# platform_designer_hps_system_hps_0_hps register map
Vendor: default_vendor.com; File version: 0.0
Registers are 32-bit, read-write, reset 0x0 unless marked. A register's access mark holds for its fields unless they carry their own. Offsets are from the block's base; [hi:lo] are bit positions; {n}, {i} and the like mark numbered series; 'fields as' and 'values as' point back to an identical list.

## usb0 (part 4 of 4) — Registers in the USB OTG Controller Module. Only the Core Global, Power and Clock Gating, Data FIFO Access, and Host Port registers can be accessedin both Host and Device modes. When the USB OTG Controller is operating in one mode, either Device or Host, the application must not access registers from the other mode. If an illegal access occurs, a Mode Mismatch interrupt is generated and reflected in the Core Interrupt register (GINTSTS.ModeMis). When the core switches from one mode to another, the registers in the new mode must be reprogrammed as they would be after a power-on reset. The register address map is fixed and does not depend on the module configuration (for example, how many endpoints are implemented). Host and Device mode registers occupy different addresses.
Base 0xFFB00000
Same registers: usb1 0xFFB40000
0x918 devgrp_dtxfsts0 ro reset 0x2000 — This register contains the free space information for the Device IN endpoint TxFIFO.
  [15:0] ineptxfspcavail — Indicates the amount of free space available in the Endpoint TxFIFO. Values are in terms of 32-bit words. 16'h0: Endpoint TxFIFO is full 16'h1: 1 word available 16'h2: 2 words available 16'hn: n words available (where 0 n 32,768) 16'h8000: 32,768 words available Others: Reserved
0x91C devgrp_diepdmab0 ro reset not defined — Endpoint 16.
  [31:0] diepdmab0 — Used with Scatter/Gather DMA.
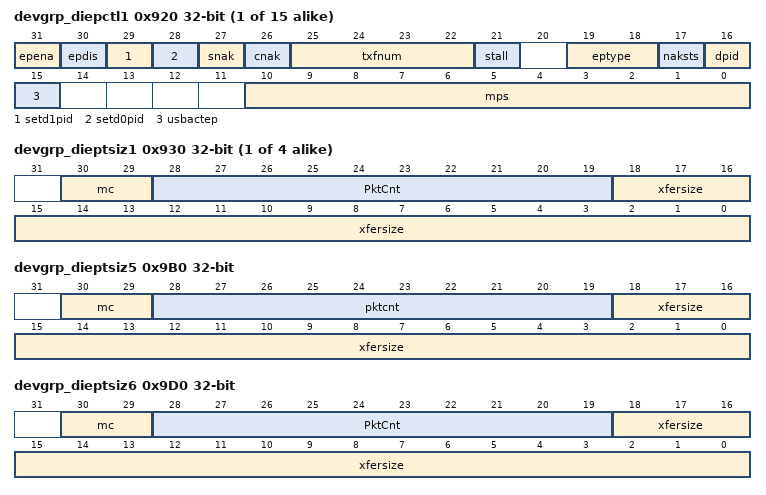
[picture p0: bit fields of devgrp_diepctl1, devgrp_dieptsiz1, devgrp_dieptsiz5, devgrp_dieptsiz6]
{0x900+0x20*i} devgrp_diepctl{i} (i=1..15) — Endpoint_number: {i}
  [31] epena ro — Applies to IN and OUT endpoints. -When Scatter/Gather DMA mode is enabled, -for IN endpoints this bit indicates that the descriptor structure and data buffer with data ready to transmit is setup. -for OUT endpoint it indicates that the descriptor structure and data buffer to receive data is setup. -When Scatter/Gather DMA mode is enabled such as for buffer-pointer based DMA mode: - for IN endpoints, this bit indicates that data is ready to be transmitted on the endpoint. - for OUT endpoints, this bit indicates that the application has allocated the memory to start receiving data from the USB. - The core clears this bit before setting any of the following interrupts on this endpoint: -SETUP Phase Done -Endpoint Disabled -Transfer Completed for control endpoints in DMA mode, this bit must be set to be able to transfer SETUP data packets in memory.
    0=inactive; 1=active
  [30] epdis ro — Applies to IN and OUT endpoints. The application sets this bit to stop transmitting/receiving data on an endpoint, even before the transfer for that endpoint is complete. The application must wait for the Endpoint Disabled interrupt before treating the endpoint as disabled. The core clears this bit before setting the Endpoint Disabled interrupt. The application must set this bit only if Endpoint Enable is already set for this endpoint.
    0=inactive; 1=active
  [29] setd1pid wo — Applies to interrupt/bulk IN and OUT endpoints only. Writing to this field sets the Endpoint Data PID (DPID) field in this register to DATA1. This field is applicable both for Scatter/Gather DMA mode and non-Scatter/Gather DMA mode. Set Odd (micro)frame (SetOddFr) Applies to isochronous IN and OUT endpoints only. Writing to this field sets the Even/Odd (micro)frame (EO_FrNum) field to odd (micro)frame.This field is not applicable for Scatter/Gather DMA mode.
    0=disabled; 1=enabled
  [28] setd0pid wo — Applies to interrupt/bulk IN and OUT endpoints only. Writing to this field sets the Endpoint Data PID (DPID) field in this register to DATA0. This field is applicable both for Scatter/Gather DMA mode and non-Scatter/Gather DMA mode. In non-Scatter/Gather DMA mode: Set Even (micro)frame (SetEvenFr) Applies to isochronous IN and OUT endpoints only. Writing to this field sets the Even/Odd (micro)frame (EO_FrNum) field to even (micro) frame. When Scatter/Gather DMA mode is enabled, this field is reserved. The frame number in which to send data is in the transmit descriptor structure. The frame in which to receive data is updated in receive descriptor structure.
    0=disabled; 1=enabled
  [27] snak wo — A write to this bit sets the NAK bit for the endpoint. Using this bit, the application can control the transmission of NAK handshakes on an endpoint. The core can also Set this bit for an endpoint after a SETUP packet is received on that endpoint.
    0=inactive; 1=active
  [26] cnak wo — A write to this bit clears the NAK bit for the endpoint.
    0=inactive; 1=active
  [25:22] txfnum — Shared FIFO Operation-non-periodic endpoints must set this bit to zero. Periodic endpoints must map this to the corresponding Periodic TxFIFO number. 4'h0: Non-Periodic TxFIFO Others: Specified Periodic TxFIFO.number An interrupt IN endpoint can be configured as a non-periodic endpoint for applications such as mass storage. The core treats an IN endpoint as a non-periodic endpoint if the TxFNum field is set to 0. Configuring an interrupt IN endpoint as a non-periodic endpoint saves the extra periodic FIFO area. Dedicated FIFO Operation-these bits specify the FIFO number associated with this endpoint. Each active IN endpoint must be programmed to a separate FIFO number. This field is valid only for IN endpoints.
  [21] stall ro — Applies to non-control, non-isochronous IN and OUT endpoints only. The application sets this bit to stall all tokens from the USB host to this endpoint. If a NAK bit, Global Non-periodic IN NAK, or Global OUT NAK is set along with this bit, the STALL bit takes priority. Only the application can clear this bit, never the core. Applies to control endpoints only. The application can only set this bit, and the core clears it, when a SETUP token is received for this endpoint. If a NAK bit, Global Non-periodic IN NAK, or Global OUT NAK is set along with this bit, the STALL bit takes priority. Irrespective of this bit's setting, the core always responds to SETUP data packets with an ACK handshake.
    0=inactive; 1=active
  [19:18] eptype — This is the transfer type supported by this logical endpoint.
    0=control; 1=isochronous; 2=bulk; 3=interrup
  [17] naksts ro — When either the application or the core sets this bit: -The core stops receiving any data on an OUT endpoint, even if there is space in the RxFIFO to accommodate the incoming packet. -for non-isochronous IN endpoints: The core stops transmitting any data on an IN endpoint, even if there data is available in the TxFIFO. -for isochronous IN endpoints: The core sends out a zero-length data packet, even if there data is available in the TxFIFO. Irrespective of this bit's setting, the core always responds to SETUP data packets with an ACK handshake.
    0=nonnak; 1=nak
  [16] dpid ro — Applies to interrupt/bulk IN and OUT endpoints only. Contains the PID of the packet to be received or transmitted on this endpoint. The application must program the PID of the first packet to be received or transmitted on this endpoint, after the endpoint is activated. The applications use the SetD1PID and SetD0PID fields of this register to program either DATA0 or DATA1 PID. 0: DATA0 1: DATA1This field is applicable both for Scatter/Gather DMA mode and non-Scatter/Gather DMA mode. Even/Odd (Micro)Frame (EO_FrNum) In non-Scatter/Gather DMA mode: Applies to isochronous IN and OUT endpoints only. Indicates the (micro)frame number in which the core transmits/receives isochronous data for this endpoint. The application must program the even/odd (micro) frame number in which it intends to transmit/receive isochronous data for this endpoint using the SetEvnFr and SetOddFr fields in this register. 0: Even (micro)frame 1: Odd (micro)frame When Scatter/Gather DMA mode is enabled, this field is reserved. The frame number in which to send data is provided in the transmit descriptor structure. The frame in which data is received is updated in receive descriptor structure.
    0=inactive; 1=active
  [15] usbactep — Indicates whether this endpoint is active in the current configuration and interface. The core clears this bit for all endpoints (other than EP 0) after detecting a USB reset. After receiving the SetConfiguration and SetInterface commands, the application must program endpoint registers accordingly and set this bit.
    0=disabled; 1=enabled
  [10:0] mps — Applies to IN and OUT endpoints. The application must program this field with the maximum packet size for the current logical endpoint. This value is in bytes.
{0x910+0x20*i} devgrp_dieptsiz{i} (i=1..4) — The application must modify this register before enabling the endpoint. Once the endpoint is enabled using Endpoint Enable bit of the Device Endpoint-n Control registers (DIEPCTLn.EPEna/DOEPCTLn.EPEna), the core modifies this register. The application can only read this register once the core has cleared the Endpoint Enable bit.
  [30:29] mc — for periodic IN endpoints, this field indicates the number of packets that must be transmitted per microframe on the USB. The core uses this field to calculate the data PID for isochronous IN endpoints. for non-periodic IN endpoints, this field is valid only in Internal DMA mode. It specifies the number of packets the core must fetchfor an IN endpoint before it switches to the endpoint pointed to by the Next Endpoint field of the Device Endpoint-n Control register (DIEPCTLn.NextEp)
    1=packetone; 2=packettwo; 3=packetthree
  [28:19] PktCnt — Indicates the total number of USB packets that constitute the Transfer Size amount of data for endpoint 0.This field is decremented every time a packet (maximum size or short packet) is read from the TxFIFO.
  [18:0] xfersize — Indicates the transfer size in bytes for endpoint 0. The core interrupts the application only after it has exhausted the transfer size amount of data. The transfer size can be Set to the maximum packet size of the endpoint, to be interrupted at the end of each packet. The core decrements this field every time a packet from the external memory is written to the TxFIFO.
0x938 devgrp_dtxfsts1 ro reset 0x2000 — This register contains the free space information for the Device IN endpoint TxFIFO.
  fields as devgrp_dtxfsts0
{0x91C+0x20*i} devgrp_diepdmab{i} ro reset not defined (i=1..4) — DMA Buffer Address.
  [31:0] diepdmab{i} — Holds the current buffer address. This register is updated as and when the data transfer for the corresponding end point is in progress. This register is present only in Scatter/Gather DMA mode.
0x958 devgrp_DTXFSTS2 ro reset 0x2000 — This register contains the free space information for the Device IN endpoint TxFIFO.
  fields as devgrp_dtxfsts0
{0x918+0x20*i} devgrp_dtxfsts{i} ro reset 0x2000 (i=3..15) — This register contains the free space information for the Device IN endpoint TxFIFO.
  fields as devgrp_dtxfsts0
0x9B0 devgrp_dieptsiz5 — The application must modify this register before enabling the endpoint. Once the endpoint is enabled using Endpoint Enable bit of the Device Endpoint-n Control registers (DIEPCTLn.EPEna/DOEPCTLn.EPEna), the core modifies this register. The application can only read this register once the core has cleared the Endpoint Enable bit.
  [30:29] mc — for periodic IN endpoints, this field indicates the number of packets that must be transmitted per microframe on the USB. The core uses this field to calculate the data PID for isochronous IN endpoints. for non-periodic IN endpoints, this field is valid only in Internal DMA mode. It specifies the number of packets the core must fetchfor an IN endpoint before it switches to the endpoint pointed to by the Next Endpoint field of the Device Endpoint-n Control register (DIEPCTLn.NextEp)
    1=packetone; 2=packettwo; 3=packetthree
  [28:19] pktcnt — Indicates the total number of USB packets that constitute the Transfer Size amount of data for endpoint 0.This field is decremented every time a packet (maximum size or short packet) is read from the TxFIFO.
  [18:0] xfersize — Indicates the transfer size in bytes for endpoint 0. The core interrupts the application only after it has exhausted the transfer size amount of data. The transfer size can be Set to the maximum packet size of the endpoint, to be interrupted at the end of each packet. The core decrements this field every time a packet from the external memory is written to the TxFIFO.
0x9BC devgrp_diepdmab5 ro reset not defined — Device IN Endpoint 1 Buffer Address.
  [31:0] diepdmab5 — Holds the current buffer address. This register is updated as and when the data transfer for the corresponding end point is in progress. This register is present only in Scatter/Gather DMA mode.
0x9D0 devgrp_dieptsiz6 — The application must modify this register before enabling the endpoint. Once the endpoint is enabled using Endpoint Enable bit of the Device Endpoint-n Control registers (DIEPCTLn.EPEna/DOEPCTLn.EPEna), the core modifies this register. The application can only read this register once the core has cleared the Endpoint Enable bit.
  fields as devgrp_dieptsiz1
{0x91C+0x20*i} devgrp_diepdmab{i} ro reset not defined (i=6..15) — DMA Buffer Address.
  fields as devgrp_diepdmab1
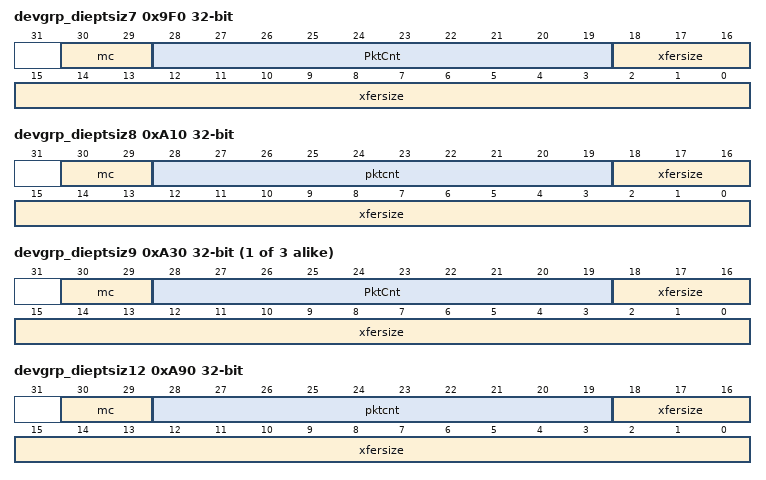
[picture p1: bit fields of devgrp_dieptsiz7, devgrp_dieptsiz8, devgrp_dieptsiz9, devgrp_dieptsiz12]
0x9F0 devgrp_dieptsiz7 — The application must modify this register before enabling the endpoint. Once the endpoint is enabled using Endpoint Enable bit of the Device Endpoint-n Control registers (DIEPCTLn.EPEna/DOEPCTLn.EPEna), the core modifies this register. The application can only read this register once the core has cleared the Endpoint Enable bit.
  fields as devgrp_dieptsiz1
0xA10 devgrp_dieptsiz8 — The application must modify this register before enabling the endpoint. Once the endpoint is enabled using Endpoint Enable bit of the Device Endpoint-n Control registers (DIEPCTLn.EPEna/DOEPCTLn.EPEna), the core modifies this register. The application can only read this register once the core has cleared the Endpoint Enable bit.
  fields as devgrp_dieptsiz5
{0x910+0x20*i} devgrp_dieptsiz{i} (i=9..11) — The application must modify this register before enabling the endpoint. Once the endpoint is enabled using Endpoint Enable bit of the Device Endpoint-n Control registers (DIEPCTLn.EPEna/DOEPCTLn.EPEna), the core modifies this register. The application can only read this register once the core has cleared the Endpoint Enable bit.
  fields as devgrp_dieptsiz1
0xA90 devgrp_dieptsiz12 — The application must modify this register before enabling the endpoint. Once the endpoint is enabled using Endpoint Enable bit of the Device Endpoint-n Control registers (DIEPCTLn.EPEna/DOEPCTLn.EPEna), the core modifies this register. The application can only read this register once the core has cleared the Endpoint Enable bit.
  fields as devgrp_dieptsiz5
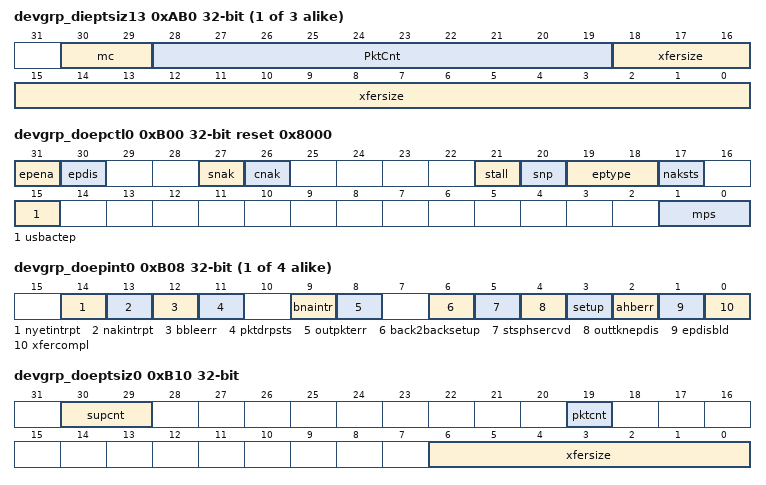
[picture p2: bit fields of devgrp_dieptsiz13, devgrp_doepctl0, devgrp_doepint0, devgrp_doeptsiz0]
{0x910+0x20*i} devgrp_dieptsiz{i} (i=13..15) — The application must modify this register before enabling the endpoint. Once the endpoint is enabled using Endpoint Enable bit of the Device Endpoint-n Control registers (DIEPCTLn.EPEna/DOEPCTLn.EPEna), the core modifies this register. The application can only read this register once the core has cleared the Endpoint Enable bit.
  fields as devgrp_dieptsiz1
0xB00 devgrp_doepctl0 reset 0x8000 — This is Control OUT Endpoint 0 Control register.
  [31] epena ro — When Scatter/Gather DMA mode is enabled, for OUT endpoints this bit indicates that the descriptor structure and data buffer to receive data is setup. When Scatter/Gather DMA mode is disabled(such as for buffer-pointer based DMA mode)this bit indicates that the application has allocated the memory to start receiving data from the USB.The core clears this bit before setting any of the following interrupts on this endpoint: SETUP Phase Done Endpoint Disabled Transfer Completed In DMA mode, this bit must be Set for the core to transfer SETUP data packets into memory.
    0=inactive; 1=active
  [30] epdis ro — The application cannot disable control OUT endpoint 0.
    0=inactive
  [27] snak wo — A write to this bit sets the NAK bit for the endpoint.Using this bit, the application can control the transmission of NAK handshakes on an endpoint. The core can also Set bit on a Transfer Completed interrupt, or after a SETUP is received on the endpoint.
    0=noset; 1=set
  [26] cnak wo — A write to this bit clears the NAK bit for the endpoint.
    0=noclear; 1=clear
  [21] stall ro — The application can only Set this bit, and the core clears it, when a SETUP token is received for this endpoint. If a NAK bit or Global OUT NAK is Set along with this bit, the STALL bit takes priority. Irrespective of this bit's setting, the core always responds to SETUP data packets with an ACK handshake.
    0=inactive; 1=active
  [20] snp — This bit configures the endpoint to Snoop mode. In Snoop mode, the core does not check the correctness of OUT packets before transferring them to application memory.
    0=disabled; 1=enabled
  [19:18] eptype ro — Hardcoded to 0 for control.
    0=active
  [17] naksts ro — When either the application or the core sets this bit, the core stops receiving data, even If there is space in the RxFIFO to accommodate the incoming packet. Irrespective of this bit's setting, the core always responds to SETUP data packets with an ACK handshake.
    0=inactive; 1=active
  [15] usbactep ro — This bit is always Set to 1, indicating that a control endpoint 0 is always active in all configurations and interfaces.
    1=active
  [1:0] mps ro — The maximum packet size for control OUT endpoint 0 is thesame as what is programmed in control IN Endpoint 0.
    0=byte64; 1=byte32; 2=byte16; 3=byte8
{0xB08+0x20*i} devgrp_doepint{i} ro (i=0..3) — This register indicates the status of an endpoint with respect to USB- and AHB-related events. The application must read this register when the OUT Endpoints Interrupt bit or IN Endpoints Interrupt bit of the Core Interrupt register (GINTSTS.OEPInt or GINTSTS.IEPInt, respectively) is set. Before the application can read this register, it must first read the Device All Endpoints Interrupt (DAINT) register to get the exact endpoint number for the Device Endpoint-n Interrupt register. The application must clear the appropriate bit in this register to clear the corresponding bits in the DAINT and GINTSTS registers.
  [all] fields
    0=inactive; 1=active
  [14] nyetintrpt — The core generates this interrupt when a NYET response is transmitted for a non isochronous OUT endpoint.
  [13] nakintrpt — The core generates this interrupt when a NAK is transmitted or received by the device. In case of isochronous IN endpoints the interrupt gets generated when a zero length packet is transmitted due to un-availability of data in the TXFifo.
  [12] bbleerr — The core generates this interrupt when babble is received for the endpoint.
  [11] pktdrpsts — This bit indicates to the application that an ISOC OUT packet has been dropped. This bit does not have an associated mask bit and does not generate an interrupt.
  [9] bnaintr — This bit is valid only when Scatter/Gather DMA mode is This bit is valid only when Scatter/Gather DMA mode is enabled. The core generates this interrupt when the descriptor accessed is not ready for the Core to process, such as Host busy or DMA done
  [8] outpkterr — Applies to OUT endpoints Only This interrupt is asserted when the core detects an overflow or a CRC error for non-Isochronous OUT packet.
  [6] back2backsetup — Applies to Control OUT endpoints only. This bit indicates that the core has received more than three back-to-back SETUP packets for this particular endpoint. for information about handling this interrupt,
  [5] stsphsercvd — This interrupt is valid only for Control OUT endpoints and only in Scatter Gather DMA mode. This interrupt is generated only after the core has transferred all the data that the host has sent during the data phase of a control write transfer, to the system memory buffer. The interrupt indicates to the application that the host has switched from data phase to the status phase of a Control Write transfer. The application can use this interrupt to ACK or STALL the Status phase, after it has decoded the data phase. This is applicable only in Case of Scatter Gather DMA mode.
  [4] outtknepdis — Applies only to control OUT endpoints. Indicates that an OUT token was received when the endpoint was not yet enabled. This interrupt is asserted on the endpoint for which the OUT token was received.
  [3] setup — Applies to control OUT endpoints only. Indicates that the SETUP phase for the control endpoint is complete and no more back-to-back SETUP packets were received for the current control transfer. On this interrupt, the application can decode the received SETUP data packet.
  [2] ahberr — Applies to IN and OUT endpoints.This is generated only in Internal DMA mode when there is an AHB error during an AHB read/write. The application can read the corresponding endpoint DMA address register to get the error address.
  [1] epdisbld — Applies to IN and OUT endpoints. This bit indicates that the endpoint is disabled per the application's request.
  [0] xfercompl — Applies to IN and OUT endpoints.When Scatter/Gather DMA mode is enabled This field indicates that the requested data from the internal FIFO is moved to external system memory. This interrupt is generated only when the corresponding endpoint descriptor is closed, and the IOC bit for the corresponding descriptor is Set. When Scatter/Gather DMA mode is disabled, this field indicates that the programmed transfer is complete on the AHB as well as on the USB, for this endpoint.
0xB10 devgrp_doeptsiz0 — The application must modify this register before enabling endpoint 0. Once endpoint 0 is enabled using Endpoint Enable bit of the Device Control Endpoint 0 Control registers (DIEPCTL0.EPEna/DOEPCTL0.EPEna), the core modifies this register. The application can only read this register once the core has cleared the Endpoint Enable bit. Nonzero endpoints use the registers for endpoints 1 to 15. When Scatter/Gather DMA mode is enabled, this register must not be programmed by the application. If the application reads this register when Scatter/Gather DMA mode is enabled, the core returns all zeros.
  [30:29] supcnt — SETUP Packet Count (SUPCnt)This field specifies the number of back-to-back SETUP datapackets the endpoint can receive.
    1=onepacket; 2=twopacket; 3=threepacket
  [19] pktcnt — This field is decremented to zero after a packet is written into the RxFIFO.
  [6:0] xfersize — Indicates the transfer size in bytes for endpoint 0. The core interrupts the application only after it has exhausted the transfer size amount of data. The transfer size can be Set to the maximum packet size of the endpoint, to be interrupted at the end of each packet. The core decrements this field every time a packet from the external memory is written to the RxFIFO.
{0xB14+0x20*i} devgrp_doepdma{i} reset not defined (i=0..2) — DMA Addressing.
  [31:0] doepdma{i} — Holds the start address of the external memory for storing or fetching endpoint data. for control endpoints, this field stores control OUT data packets as well as SETUP transaction data packets. When more than three SETUP packets are received back-to-back, the SETUP data packet in the memory is overwritten. This register is incremented on every AHB transaction. The application can give only a DWORD-aligned address. When Scatter/Gather DMA mode is not enabled, the application programs the start address value in this field. When Scatter/Gather DMA mode is enabled, this field indicates the base pointer for the descriptor list.
0xB1C devgrp_doepdmab0 ro reset not defined — DMA Buffer Address.
  [31:0] doepdmab0 — Used with Scatter/Gather DMA.
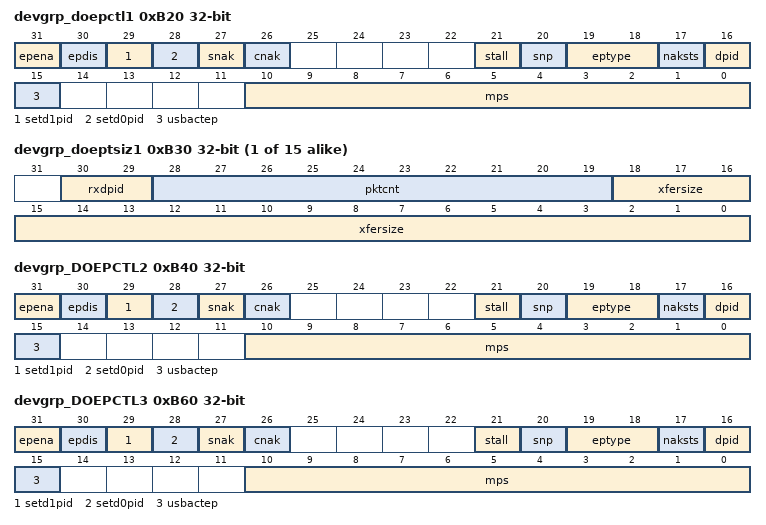
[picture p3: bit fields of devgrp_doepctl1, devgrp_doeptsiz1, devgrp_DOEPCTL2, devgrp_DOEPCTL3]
0xB20 devgrp_doepctl1 — Out Endpoint 1.
  [31] epena ro — Applies to IN and OUT endpoints. -When Scatter/Gather DMA mode is enabled, -for IN endpoints this bit indicates that the descriptor structure and data buffer with data ready to transmit is setup. -for OUT endpoint it indicates that the descriptor structure and data buffer to receive data is setup. -When Scatter/Gather DMA mode is enabled such as for buffer-pointer based DMA mode: - for IN endpoints, this bit indicates that data is ready to be transmitted on the endpoint. - for OUT endpoints, this bit indicates that the application has allocated the memory to start receiving data from the USB. - The core clears this bit before setting any of the following interrupts on this endpoint: -SETUP Phase Done -Endpoint Disabled -Transfer Completed for control endpoints in DMA mode, this bit must be set to be able to transfer SETUP data packets in memory.
    0=inactive; 1=active
  [30] epdis ro — Applies to IN and OUT endpoints. The application sets this bit to stop transmitting/receiving data on an endpoint, even before the transfer for that endpoint is complete. The application must wait for the Endpoint Disabled interrupt before treating the endpoint as disabled. The core clears this bit before setting the Endpoint Disabled interrupt. The application must set this bit only if Endpoint Enable is already set for this endpoint.
    0=inactive; 1=active
  [29] setd1pid wo — Applies to interrupt/bulk IN and OUT endpoints only. Writing to this field sets the Endpoint Data PID (DPID) field in this register to DATA1. This field is applicable both for Scatter/Gather DMA mode and non-Scatter/Gather DMA mode. Set Odd (micro)frame (SetOddFr) Applies to isochronous IN and OUT endpoints only. Writing to this field sets the Even/Odd (micro)frame (EO_FrNum) field to odd (micro)frame.This field is not applicable for Scatter/Gather DMA mode.
    0=disabled; 1=enabled
  [28] setd0pid wo — Applies to interrupt/bulk IN and OUT endpoints only. Writing to this field sets the Endpoint Data PID (DPID) field in this register to DATA0. This field is applicable both for Scatter/Gather DMA mode and non-Scatter/Gather DMA mode. In non-Scatter/Gather DMA mode: Set Even (micro)frame (SetEvenFr) Applies to isochronous IN and OUT endpoints only. Writing to this field sets the Even/Odd (micro)frame (EO_FrNum) field to even (micro) frame. When Scatter/Gather DMA mode is enabled, this field is reserved. The frame number in which to send data is in the transmit descriptor structure. The frame in which to receive data is updated in receive descriptor structure.
    0=disabled; 1=enabled
  [27] snak wo — A write to this bit sets the NAK bit for the endpoint. Using this bit, the application can control the transmission of NAK handshakes on an endpoint. The core can also Set this bit for an endpoint after a SETUP packet is received on that endpoint.
    0=inactive; 1=active
  [26] cnak wo — A write to this bit clears the NAK bit for the endpoint.
    0=inactive; 1=active
  [21] stall ro — Applies to non-control, non-isochronous IN and OUT endpoints only. The application sets this bit to stall all tokens from the USB host to this endpoint. If a NAK bit, Global Non-periodic IN NAK, or Global OUT NAK is set along with this bit, the STALL bit takes priority. Only the application can clear this bit, never the core. Applies to control endpoints only. The application can only set this bit, and the core clears it, when a SETUP token is received for this endpoint. If a NAK bit, Global Non-periodic IN NAK, or Global OUT NAK is set along with this bit, the STALL bit takes priority. Irrespective of this bit's setting, the core always responds to SETUP data packets with an ACK handshake.
    0=inactive; 1=active
  [20] snp — Applies to OUT endpoints only. This bit configures the endpoint to Snoop mode. In Snoop mode, the core does not check the correctness of OUT packets before transferring them to application memory.
    0=disable; 1=enable
  [19:18] eptype — This is the transfer type supported by this logical endpoint.
    0=control; 1=isochronous; 2=bulk; 3=interrup
  [17] naksts ro — When either the application or the core sets this bit: -The core stops receiving any data on an OUT endpoint, even if there is space in the RxFIFO to accommodate the incoming packet. -for non-isochronous IN endpoints: The core stops transmitting any data on an IN endpoint, even if there data is available in the TxFIFO. -for isochronous IN endpoints: The core sends out a zero-length data packet, even if there data is available in the TxFIFO. Irrespective of this bit's setting, the core always responds to SETUP data packets with an ACK handshake.
    0=nonnak; 1=nak
  [16] dpid ro — Applies to interrupt/bulk IN and OUT endpoints only. Contains the PID of the packet to be received or transmitted on this endpoint. The application must program the PID of the first packet to be received or transmitted on this endpoint, after the endpoint is activated. The applications use the SetD1PID and SetD0PID fields of this register to program either DATA0 or DATA1 PID. 0: DATA0 1: DATA1This field is applicable both for Scatter/Gather DMA mode and non-Scatter/Gather DMA mode. Even/Odd (Micro)Frame (EO_FrNum) In non-Scatter/Gather DMA mode: Applies to isochronous IN and OUT endpoints only. Indicates the (micro)frame number in which the core transmits/receives isochronous data for this endpoint. The application must program the even/odd (micro) frame number in which it intends to transmit/receive isochronous data for this endpoint using the SetEvnFr and SetOddFr fields in this register. h 1'b0'b0: Even (micro)frame 1: Odd (micro)frame When Scatter/Gather DMA mode is enabled, this field is reserved. The frame number in which to send data is provided in the transmit descriptor structure. The frame in which data is received is updated in receive descriptor structure.
    0=inactive; 1=active
  [15] usbactep — Indicates whether this endpoint is active in the current configuration and interface. The core clears this bit for all endpoints (other than EP 0) after detecting a USB reset. After receiving the SetConfiguration and SetInterface commands, the application must program endpoint registers accordingly and set this bit.
    0=disabled; 1=enabled
  [10:0] mps — Applies to IN and OUT endpoints. The application must program this field with the maximum packet size for the current logical endpoint. This value is in bytes.
{0xB10+0x20*i} devgrp_doeptsiz{i} (i=1..15) — The application must modify this register before enabling the endpoint. Once the endpoint is enabled using Endpoint Enable bit of the Device Endpoint-n Control registers (DIEPCTLn.EPEna/DOEPCTLn.EPEna), the core modifies this register. The application can only read this register once the core has cleared the Endpoint Enable bit.
  [30:29] rxdpid ro — Applies to isochronous OUT endpoints only.This is the data PID received in the last packet for this endpoint. Use datax. Applies to control OUT Endpoints only. Use packetx. This field specifies the number of back-to-back SETUP data packets the endpoint can receive.
    0=data0; 1=data2packet1; 2=data1packet2; 3=mdatapacket3
  [28:19] pktcnt — Indicates the total number of USB packets that constitute the Transfer Size amount of data for endpoint 0.This field is decremented every time a packet (maximum size or short packet) is read from the RxFIFO.
  [18:0] xfersize — Indicates the transfer size in bytes for endpoint 0. The core interrupts the application only after it has exhausted the transfer size amount of data. The transfer size can be Set to the maximum packet size of the endpoint, to be interrupted at the end of each packet. The core decrements this field every time a packet from the external memory is written to the RxFIFO.
{0xB1C+0x20*i} devgrp_doepdmab{i} ro reset not defined (i=1..15) — DMA Buffer Address.
  [31:0] doepdmab{i} — Holds the current buffer address. This register is updated as and when the data transfer for the corresponding end point is in progress. This register is present only in Scatter/Gather DMA mode.
0xB40 devgrp_DOEPCTL2 — Out Endpoint 2.
  [31] epena ro — Applies to IN and OUT endpoints. -When Scatter/Gather DMA mode is enabled, -for IN endpoints this bit indicates that the descriptor structure and data buffer with data ready to transmit is setup. -for OUT endpoint it indicates that the descriptor structure and data buffer to receive data is setup. -When Scatter/Gather DMA mode is enabled such as for buffer-pointer based DMA mode: - for IN endpoints, this bit indicates that data is ready to be transmitted on the endpoint. - for OUT endpoints, this bit indicates that the application has allocated the memory to start receiving data from the USB. - The core clears this bit before setting any of the following interrupts on this endpoint: -SETUP Phase Done -Endpoint Disabled -Transfer Completed for control endpoints in DMA mode, this bit must be set to be able to transfer SETUP data packets in memory.
    0=inactive; 1=active
  [30] epdis ro — Applies to IN and OUT endpoints. The application sets this bit to stop transmitting/receiving data on an endpoint, even before the transfer for that endpoint is complete. The application must wait for the Endpoint Disabled interrupt before treating the endpoint as disabled. The core clears this bit before setting the Endpoint Disabled interrupt. The application must set this bit only if Endpoint Enable is already set for this endpoint.
    0=inactive; 1=active
  [29] setd1pid wo — Applies to interrupt/bulk IN and OUT endpoints only. Writing to this field sets the Endpoint Data PID (DPID) field in this register to DATA1. This field is applicable both for Scatter/Gather DMA mode and non-Scatter/Gather DMA mode. Set Odd (micro)frame (SetOddFr) Applies to isochronous IN and OUT endpoints only. Writing to this field sets the Even/Odd (micro)frame (EO_FrNum) field to odd (micro)frame.This field is not applicable for Scatter/Gather DMA mode.
    0=disabled; 1=enabled
  [28] setd0pid wo — Applies to interrupt/bulk IN and OUT endpoints only. Writing to this field sets the Endpoint Data PID (DPID) field in this register to DATA0. This field is applicable both for Scatter/Gather DMA mode and non-Scatter/Gather DMA mode. In non-Scatter/Gather DMA mode: Set Even (micro)frame (SetEvenFr) Applies to isochronous IN and OUT endpoints only. Writing to this field sets the Even/Odd (micro)frame (EO_FrNum) field to even (micro) frame. When Scatter/Gather DMA mode is enabled, this field is reserved. The frame number in which to send data is in the transmit descriptor structure. The frame in which to receive data is updated in receive descriptor structure.
    0=disabled; 1=enabled
  [27] snak wo — A write to this bit sets the NAK bit for the endpoint. Using this bit, the application can control the transmission of NAK handshakes on an endpoint. The core can also Set this bit for an endpoint after a SETUP packet is received on that endpoint.
    0=inactive; 1=active
  [26] cnak wo — A write to this bit clears the NAK bit for the endpoint.
    0=inactive; 1=active
  [21] stall ro — Applies to non-control, non-isochronous IN and OUT endpoints only. The application sets this bit to stall all tokens from the USB host to this endpoint. If a NAK bit, Global Non-periodic IN NAK, or Global OUT NAK is set along with this bit, the STALL bit takes priority. Only the application can clear this bit, never the core. Applies to control endpoints only. The application can only set this bit, and the core clears it, when a SETUP token is received for this endpoint. If a NAK bit, Global Non-periodic IN NAK, or Global OUT NAK is set along with this bit, the STALL bit takes priority. Irrespective of this bit's setting, the core always responds to SETUP data packets with an ACK handshake.
    0=inactive; 1=active
  [20] snp — Applies to OUT endpoints only. This bit configures the endpoint to Snoop mode. In Snoop mode, the core does not check the correctness of OUT packets before transferring them to application memory.
    0=disable; 1=enable
  [19:18] eptype — This is the transfer type supported by this logical endpoint.
    0=control; 1=isochronous; 2=bulk; 3=interrup
  [17] naksts ro — When either the application or the core sets this bit: -The core stops receiving any data on an OUT endpoint, even if there is space in the RxFIFO to accommodate the incoming packet. -for non-isochronous IN endpoints: The core stops transmitting any data on an IN endpoint, even if there data is available in the TxFIFO. -for isochronous IN endpoints: The core sends out a zero-length data packet, even if there data is available in the TxFIFO. Irrespective of this bit's setting, the core always responds to SETUP data packets with an ACK handshake.
    0=nonnak; 1=nak
  [16] dpid ro — Applies to interrupt/bulk IN and OUT endpoints only. Contains the PID of the packet to be received or transmitted on this endpoint. The application must program the PID of the first packet to be received or transmitted on this endpoint, after the endpoint is activated. The applications use the SetD1PID and SetD0PID fields of this register to program either DATA0 or DATA1 PID. 0: DATA0 1: DATA1This field is applicable both for Scatter/Gather DMA mode and non-Scatter/Gather DMA mode. Even/Odd (Micro)Frame (EO_FrNum) In non-Scatter/Gather DMA mode: Applies to isochronous IN and OUT endpoints only. Indicates the (micro)frame number in which the core transmits/receives isochronous data for this endpoint. The application must program the even/odd (micro) frame number in which it intends to transmit/receive isochronous data for this endpoint using the SetEvnFr and SetOddFr fields in this register. 0: Even (micro)frame 1: Odd (micro)frame When Scatter/Gather DMA mode is enabled, this field is reserved. The frame number in which to send data is provided in the transmit descriptor structure. The frame in which data is received is updated in receive descriptor structure.
    0=inactive; 1=active
  [15] usbactep — Indicates whether this endpoint is active in the current configuration and interface. The core clears this bit for all endpoints (other than EP 0) after detecting a USB reset. After receiving the SetConfiguration and SetInterface commands, the application must program endpoint registers accordingly and set this bit.
    0=disabled; 1=enabled
  [10:0] mps — Applies to IN and OUT endpoints. The application must program this field with the maximum packet size for the current logical endpoint. This value is in bytes.
0xB60 devgrp_DOEPCTL3 — Out Endpoint 3.
  fields as devgrp_DOEPCTL2
{0xB14+0x20*i} devgrp_doepdma{i} reset not defined (i=3..15) — DMA OUT Address.
  fields as devgrp_doepdma0
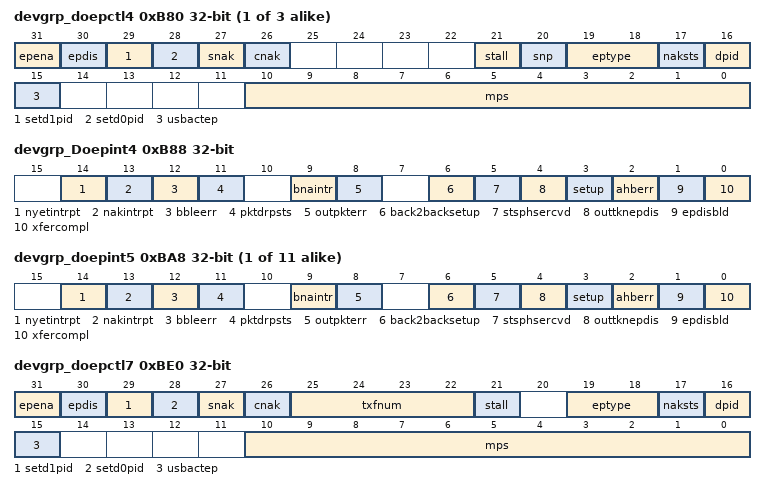
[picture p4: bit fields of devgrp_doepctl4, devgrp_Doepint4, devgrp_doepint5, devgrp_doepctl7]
{0xB00+0x20*i} devgrp_doepctl{i} (i=4..6) — Out Endpoint {i}.
  fields as devgrp_DOEPCTL2
0xB88 devgrp_Doepint4 ro — This register indicates the status of an endpoint with respect to USB- and AHB-related events. The application must read this register when the OUT Endpoints Interrupt bit or IN Endpoints Interrupt bit of the Core Interrupt register (GINTSTS.OEPInt or GINTSTS.IEPInt, respectively) is set. Before the application can read this register, it must first read the Device All Endpoints Interrupt (DAINT) register to get the exact endpoint number for the Device Endpoint-n Interrupt register. The application must clear the appropriate bit in this register to clear the corresponding bits in the DAINT and GINTSTS registers.
  fields as devgrp_doepint0
{0xB08+0x20*i} devgrp_doepint{i} ro (i=5..15) — This register indicates the status of an endpoint with respect to USB- and AHB-related events. The application must read this register when the OUT Endpoints Interrupt bit or IN Endpoints Interrupt bit of the Core Interrupt register (GINTSTS.OEPInt or GINTSTS.IEPInt, respectively) is set. Before the application can read this register, it must first read the Device All Endpoints Interrupt (DAINT) register to get the exact endpoint number for the Device Endpoint-n Interrupt register. The application must clear the appropriate bit in this register to clear the corresponding bits in the DAINT and GINTSTS registers.
  fields as devgrp_doepint0
0xBE0 devgrp_doepctl7 — Endpoint_number: 7
  fields as devgrp_diepctl1
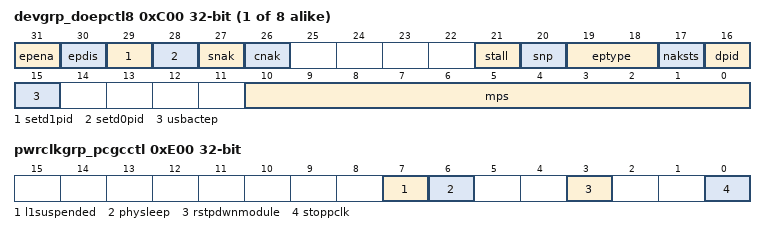
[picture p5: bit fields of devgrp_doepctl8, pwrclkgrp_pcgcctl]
{0xB00+0x20*i} devgrp_doepctl{i} (i=8..15) — Out Endpoint {i}.
  fields as devgrp_DOEPCTL2
0xE00 pwrclkgrp_pcgcctl — This register is available in Host and Device modes. The application can use this register to control the core's power-down and clock gating features. Because the CSR module is turned off during power-down, this register is implemented in the AHB Slave BIU module.
  [7] l1suspended ro — Indicates that the PHY is in deep sleep when in L1 state.
    0=inactive; 1=active
  [6] physleep ro — Indicates that the PHY is in Sleep State.
    0=inactive; 1=active
  [3] rstpdwnmodule — This bit is valid only in Partial Power-Down mode. Theapplication sets this bit when the power is turned off. The application clears this bit after the power is turned on and the PHY clock is up. The R/W of all core registers are possible only when this bit is set to 1b0.
    0=on; 1=off
  [0] stoppclk — The application sets this bit to stop the PHY clock (phy_clk) when the USB is suspended, the session is not valid, or the device is disconnected. The application clears this bit when the USB is resumed or a new session starts.
    0=disabled; 1=enabled
